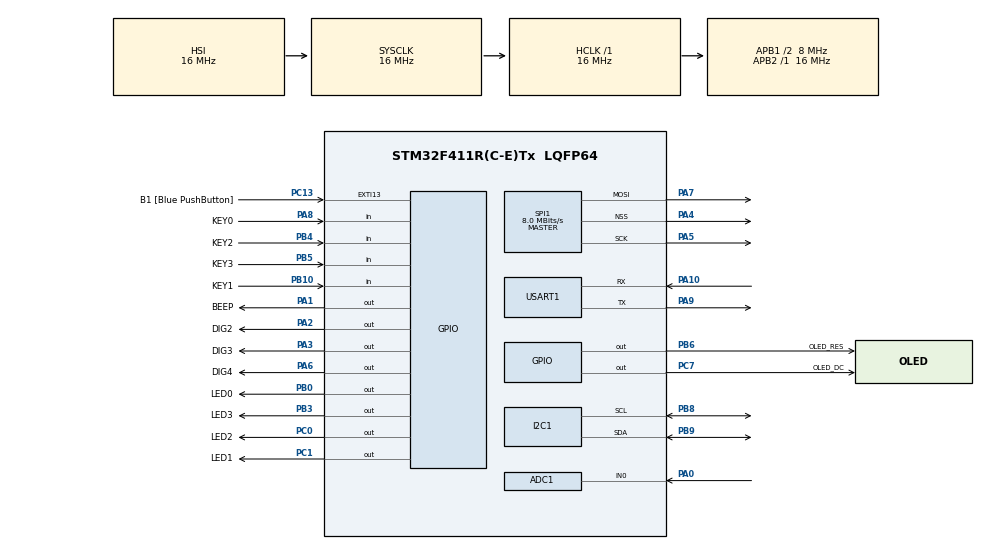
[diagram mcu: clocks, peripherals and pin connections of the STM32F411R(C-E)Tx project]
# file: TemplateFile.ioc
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ADC1.Channel-1\#ChannelRegularConversion=ADC_CHANNEL_0
ADC1.NbrOfConversionFlag=1
ADC1.Rank-1\#ChannelRegularConversion=1
ADC1.SamplingTime-1\#ChannelRegularConversion=ADC_SAMPLETIME_3CYCLES
ADC1.master=1
Mcu.Family=STM32F4
Mcu.Name=STM32F411R(C-E)Tx
Mcu.Package=LQFP64
NVIC.PriorityGroup=NVIC_PRIORITYGROUP_0
NVIC.TIM1_TRG_COM_TIM11_IRQn=true\:0\:0\:false\:false\:true\:true\:true\:true
PA0-WKUP.Signal=ADCx_IN0
PA1.GPIO_Label=BEEP
PA1.Signal=GPIO_Output
PA10.Mode=Asynchronous
PA10.Signal=USART1_RX
PA13.GPIO_Label=TMS
PA13.Mode=Serial_Wire
PA13.Signal=SYS_JTMS-SWDIO
PA14.GPIO_Label=TCK
PA14.Mode=Serial_Wire
PA14.Signal=SYS_JTCK-SWCLK
PA2.GPIO_Label=DIG2
PA2.Signal=GPIO_Output
PA3.GPIO_Label=DIG3
PA3.Signal=GPIO_Output
PA4.Mode=NSS_Signal_Hard_Output
PA4.Signal=SPI1_NSS
PA5.Mode=TX_Only_Simplex_Unidirect_Master
PA5.Signal=SPI1_SCK
PA6.GPIO_Label=DIG4
PA6.Signal=GPIO_Output
PA7.Mode=TX_Only_Simplex_Unidirect_Master
PA7.Signal=SPI1_MOSI
PA8.GPIO_Label=KEY0
PA8.Signal=GPIO_Input
PA9.Mode=Asynchronous
PA9.Signal=USART1_TX
PB0.GPIO_Label=LED0
PB0.GPIO_ModeDefaultOutputPP=GPIO_MODE_OUTPUT_PP
PB0.Signal=GPIO_Output
PB10.GPIO_Label=KEY1
PB10.Signal=GPIO_Input
PB3.GPIO_Label=LED3
PB3.Signal=GPIO_Output
PB4.GPIO_Label=KEY2
PB4.Signal=GPIO_Input
PB5.GPIO_Label=KEY3
PB5.Signal=GPIO_Input
PB6.GPIO_Label=OLED_RES
PB6.Signal=GPIO_Output
PB8.Mode=I2C
PB8.Signal=I2C1_SCL
PB9.Mode=I2C
PB9.Signal=I2C1_SDA
PC0.GPIO_Label=LED2
PC0.Signal=GPIO_Output
PC1.GPIO_Label=LED1
PC1.Signal=GPIO_Output
PC13-ANTI_TAMP.GPIO_Label=B1 [Blue PushButton]
PC13-ANTI_TAMP.GPIO_ModeDefaultEXTI=GPIO_MODE_IT_FALLING
PC13-ANTI_TAMP.Signal=GPXTI13
PC7.GPIO_Label=OLED_DC
PC7.Signal=GPIO_Output
ProjectManager.HeapSize=0x200
ProjectManager.StackSize=0x400
ProjectManager.TargetToolchain=MDK-ARM V5.32
RCC.48MHZClocksFreq_Value=50000000
RCC.AHBFreq_Value=16000000
RCC.APB1CLKDivider=RCC_HCLK_DIV2
RCC.APB1Freq_Value=8000000
RCC.APB1TimFreq_Value=16000000
RCC.APB2Freq_Value=16000000
RCC.APB2TimFreq_Value=16000000
RCC.CortexFreq_Value=16000000
RCC.FLatency-AdvancedSettings=FLASH_LATENCY_0
RCC.HCLKFreq_Value=16000000
RCC.HSE_VALUE=8000000
RCC.HSI_VALUE=16000000
RCC.PLLM=8
RCC.PLLN=100
RCC.SYSCLKFreq_VALUE=16000000
RCC.VCOOutputFreq_Value=200000000
SH.ADCx_IN0.0=ADC1_IN0,IN0
SPI1.CalculateBaudRate=8.0 MBits/s
SPI1.Direction=SPI_DIRECTION_2LINES
SPI1.Mode=SPI_MODE_MASTER
SPI1.VirtualNSS=VM_NSSHARD
SPI1.VirtualType=VM_MASTER
TIM11.Period=1000
TIM11.Prescaler=16
USART1.VirtualMode=VM_ASYNC
VP_TIM11_VS_ClockSourceINT.Mode=Enable_Timer
board=NUCLEO-F411RE

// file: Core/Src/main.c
/* USER CODE BEGIN Header */
/**
  ******************************************************************************
  * @file           : main.c
  * @brief          : Main program body
  ******************************************************************************
  * @attention
  *
  * Copyright (c) 2024 STMicroelectronics.
  * All rights reserved.
  *
  * This software is licensed under terms that can be found in the LICENSE file
  * in the root directory of this software component.
  * If no LICENSE file comes with this software, it is provided AS-IS.
  *
  ******************************************************************************
  */
/* USER CODE END Header */
#include "main.h"

ADC_HandleTypeDef hadc1;

I2C_HandleTypeDef hi2c1;

SPI_HandleTypeDef hspi1;

TIM_HandleTypeDef htim11;

UART_HandleTypeDef huart1;

void SystemClock_Config(void);
static void MX_GPIO_Init(void);
static void MX_TIM11_Init(void);
static void MX_ADC1_Init(void);
static void MX_I2C1_Init(void);
static void MX_USART1_UART_Init(void);
static void MX_SPI1_Init(void);

int main(void)
{

  /* MCU Configuration--------------------------------------------------------*/

  /* Reset of all peripherals, Initializes the Flash interface and the Systick. */
  HAL_Init();

  /* Configure the system clock */
  SystemClock_Config();

  /* Initialize all configured peripherals */
  MX_GPIO_Init();
  MX_TIM11_Init();
  MX_ADC1_Init();
  MX_I2C1_Init();
  MX_USART1_UART_Init();
  MX_SPI1_Init();
  /* USER CODE BEGIN 2 */
	HAL_TIM_Base_Start_IT(&htim11);

	BSP_OLED_Init();

	BSP_OLED_CLS();
	BSP_OLED_ShowString(12, 0, (char*)"Hello Nino!");
	BSP_OLED_Refresh();

  /* USER CODE END 2 */

  /* Infinite loop */
  /* USER CODE BEGIN WHILE */

  while (1)
  {
		//userApp_1();
		userApp_2();

		static char strRuntime[16];
		sprintf(strRuntime, "Run: %dmin %2.0ds", Tim11Counter.timestamp_min
																							 , Tim11Counter.timestamp_ms/1000);
		BSP_OLED_ShowString(12, 32, strRuntime);
		BSP_OLED_Refresh();
    /* USER CODE END WHILE */

  }
}

void SystemClock_Config(void)
{
  RCC_OscInitTypeDef RCC_OscInitStruct = {0};
  RCC_ClkInitTypeDef RCC_ClkInitStruct = {0};

  /** Configure the main internal regulator output voltage
  */
  __HAL_RCC_PWR_CLK_ENABLE();
  __HAL_PWR_VOLTAGESCALING_CONFIG(PWR_REGULATOR_VOLTAGE_SCALE1);

  /** Initializes the RCC Oscillators according to the specified parameters
  * in the RCC_OscInitTypeDef structure.
  */
  RCC_OscInitStruct.OscillatorType = RCC_OSCILLATORTYPE_HSI;
  RCC_OscInitStruct.HSIState = RCC_HSI_ON;
  RCC_OscInitStruct.HSICalibrationValue = RCC_HSICALIBRATION_DEFAULT;
  RCC_OscInitStruct.PLL.PLLState = RCC_PLL_NONE;
  if (HAL_RCC_OscConfig(&RCC_OscInitStruct) != HAL_OK)
  {
    Error_Handler();
  }

  /** Initializes the CPU, AHB and APB buses clocks
  */
  RCC_ClkInitStruct.ClockType = RCC_CLOCKTYPE_HCLK|RCC_CLOCKTYPE_SYSCLK
                              |RCC_CLOCKTYPE_PCLK1|RCC_CLOCKTYPE_PCLK2;
  RCC_ClkInitStruct.SYSCLKSource = RCC_SYSCLKSOURCE_HSI;
  RCC_ClkInitStruct.AHBCLKDivider = RCC_SYSCLK_DIV1;
  RCC_ClkInitStruct.APB1CLKDivider = RCC_HCLK_DIV2;
  RCC_ClkInitStruct.APB2CLKDivider = RCC_HCLK_DIV1;

  if (HAL_RCC_ClockConfig(&RCC_ClkInitStruct, FLASH_LATENCY_0) != HAL_OK)
  {
    Error_Handler();
  }
}

static void MX_ADC1_Init(void)
{

  ADC_ChannelConfTypeDef sConfig = {0};

  /** Configure the global features of the ADC (Clock, Resolution, Data Alignment and number of conversion)
  */
  hadc1.Instance = ADC1;
  hadc1.Init.ClockPrescaler = ADC_CLOCK_SYNC_PCLK_DIV2;
  hadc1.Init.Resolution = ADC_RESOLUTION_12B;
  hadc1.Init.ScanConvMode = DISABLE;
  hadc1.Init.ContinuousConvMode = DISABLE;
  hadc1.Init.DiscontinuousConvMode = DISABLE;
  hadc1.Init.ExternalTrigConvEdge = ADC_EXTERNALTRIGCONVEDGE_NONE;
  hadc1.Init.ExternalTrigConv = ADC_SOFTWARE_START;
  hadc1.Init.DataAlign = ADC_DATAALIGN_RIGHT;
  hadc1.Init.NbrOfConversion = 1;
  hadc1.Init.DMAContinuousRequests = DISABLE;
  hadc1.Init.EOCSelection = ADC_EOC_SINGLE_CONV;
  if (HAL_ADC_Init(&hadc1) != HAL_OK)
  {
    Error_Handler();
  }

  /** Configure for the selected ADC regular channel its corresponding rank in the sequencer and its sample time.
  */
  sConfig.Channel = ADC_CHANNEL_0;
  sConfig.Rank = 1;
  sConfig.SamplingTime = ADC_SAMPLETIME_3CYCLES;
  if (HAL_ADC_ConfigChannel(&hadc1, &sConfig) != HAL_OK)
  {
    Error_Handler();
  }

}

static void MX_I2C1_Init(void)
{

  hi2c1.Instance = I2C1;
  hi2c1.Init.ClockSpeed = 100000;
  hi2c1.Init.DutyCycle = I2C_DUTYCYCLE_2;
  hi2c1.Init.OwnAddress1 = 0;
  hi2c1.Init.AddressingMode = I2C_ADDRESSINGMODE_7BIT;
  hi2c1.Init.DualAddressMode = I2C_DUALADDRESS_DISABLE;
  hi2c1.Init.OwnAddress2 = 0;
  hi2c1.Init.GeneralCallMode = I2C_GENERALCALL_DISABLE;
  hi2c1.Init.NoStretchMode = I2C_NOSTRETCH_DISABLE;
  if (HAL_I2C_Init(&hi2c1) != HAL_OK)
  {
    Error_Handler();
  }

}

static void MX_SPI1_Init(void)
{

  /* SPI1 parameter configuration*/
  hspi1.Instance = SPI1;
  hspi1.Init.Mode = SPI_MODE_MASTER;
  hspi1.Init.Direction = SPI_DIRECTION_2LINES;
  hspi1.Init.DataSize = SPI_DATASIZE_8BIT;
  hspi1.Init.CLKPolarity = SPI_POLARITY_LOW;
  hspi1.Init.CLKPhase = SPI_PHASE_1EDGE;
  hspi1.Init.NSS = SPI_NSS_HARD_OUTPUT;
  hspi1.Init.BaudRatePrescaler = SPI_BAUDRATEPRESCALER_2;
  hspi1.Init.FirstBit = SPI_FIRSTBIT_MSB;
  hspi1.Init.TIMode = SPI_TIMODE_DISABLE;
  hspi1.Init.CRCCalculation = SPI_CRCCALCULATION_DISABLE;
  hspi1.Init.CRCPolynomial = 10;
  if (HAL_SPI_Init(&hspi1) != HAL_OK)
  {
    Error_Handler();
  }

}

static void MX_TIM11_Init(void)
{

  htim11.Instance = TIM11;
  htim11.Init.Prescaler = 16;
  htim11.Init.CounterMode = TIM_COUNTERMODE_UP;
  htim11.Init.Period = 1000;
  htim11.Init.ClockDivision = TIM_CLOCKDIVISION_DIV1;
  htim11.Init.AutoReloadPreload = TIM_AUTORELOAD_PRELOAD_DISABLE;
  if (HAL_TIM_Base_Init(&htim11) != HAL_OK)
  {
    Error_Handler();
  }

}

static void MX_USART1_UART_Init(void)
{

  huart1.Instance = USART1;
  huart1.Init.BaudRate = 115200;
  huart1.Init.WordLength = UART_WORDLENGTH_8B;
  huart1.Init.StopBits = UART_STOPBITS_1;
  huart1.Init.Parity = UART_PARITY_NONE;
  huart1.Init.Mode = UART_MODE_TX_RX;
  huart1.Init.HwFlowCtl = UART_HWCONTROL_NONE;
  huart1.Init.OverSampling = UART_OVERSAMPLING_16;
  if (HAL_UART_Init(&huart1) != HAL_OK)
  {
    Error_Handler();
  }

}

static void MX_GPIO_Init(void)
{
  GPIO_InitTypeDef GPIO_InitStruct = {0};

  /* GPIO Ports Clock Enable */
  __HAL_RCC_GPIOC_CLK_ENABLE();
  __HAL_RCC_GPIOA_CLK_ENABLE();
  __HAL_RCC_GPIOB_CLK_ENABLE();

  /*Configure GPIO pin Output Level */
  HAL_GPIO_WritePin(GPIOC, LED2_Pin|LED1_Pin|OLED_DC_Pin, GPIO_PIN_RESET);

  /*Configure GPIO pin Output Level */
  HAL_GPIO_WritePin(GPIOA, BEEP_Pin|DIG2_Pin|DIG3_Pin|DIG4_Pin, GPIO_PIN_RESET);

  /*Configure GPIO pin Output Level */
  HAL_GPIO_WritePin(GPIOB, LED0_Pin|LED3_Pin|OLED_RES_Pin, GPIO_PIN_RESET);

  /*Configure GPIO pin : B1_Pin */
  GPIO_InitStruct.Pin = B1_Pin;
  GPIO_InitStruct.Mode = GPIO_MODE_IT_FALLING;
  GPIO_InitStruct.Pull = GPIO_NOPULL;
  HAL_GPIO_Init(B1_GPIO_Port, &GPIO_InitStruct);

  /*Configure GPIO pins : LED2_Pin LED1_Pin OLED_DC_Pin */
  GPIO_InitStruct.Pin = LED2_Pin|LED1_Pin|OLED_DC_Pin;
  GPIO_InitStruct.Mode = GPIO_MODE_OUTPUT_PP;
  GPIO_InitStruct.Pull = GPIO_NOPULL;
  GPIO_InitStruct.Speed = GPIO_SPEED_FREQ_LOW;
  HAL_GPIO_Init(GPIOC, &GPIO_InitStruct);

  /*Configure GPIO pins : BEEP_Pin DIG2_Pin DIG3_Pin DIG4_Pin */
  GPIO_InitStruct.Pin = BEEP_Pin|DIG2_Pin|DIG3_Pin|DIG4_Pin;
  GPIO_InitStruct.Mode = GPIO_MODE_OUTPUT_PP;
  GPIO_InitStruct.Pull = GPIO_NOPULL;
  GPIO_InitStruct.Speed = GPIO_SPEED_FREQ_LOW;
  HAL_GPIO_Init(GPIOA, &GPIO_InitStruct);

  /*Configure GPIO pins : LED0_Pin LED3_Pin OLED_RES_Pin */
  GPIO_InitStruct.Pin = LED0_Pin|LED3_Pin|OLED_RES_Pin;
  GPIO_InitStruct.Mode = GPIO_MODE_OUTPUT_PP;
  GPIO_InitStruct.Pull = GPIO_NOPULL;
  GPIO_InitStruct.Speed = GPIO_SPEED_FREQ_LOW;
  HAL_GPIO_Init(GPIOB, &GPIO_InitStruct);

  /*Configure GPIO pins : KEY1_Pin KEY2_Pin KEY3_Pin */
  GPIO_InitStruct.Pin = KEY1_Pin|KEY2_Pin|KEY3_Pin;
  GPIO_InitStruct.Mode = GPIO_MODE_INPUT;
  GPIO_InitStruct.Pull = GPIO_NOPULL;
  HAL_GPIO_Init(GPIOB, &GPIO_InitStruct);

  /*Configure GPIO pin : KEY0_Pin */
  GPIO_InitStruct.Pin = KEY0_Pin;
  GPIO_InitStruct.Mode = GPIO_MODE_INPUT;
  GPIO_InitStruct.Pull = GPIO_NOPULL;
  HAL_GPIO_Init(KEY0_GPIO_Port, &GPIO_InitStruct);

}

void Error_Handler(void)
{
  __disable_irq();
  while (1)
  {
  }
}
